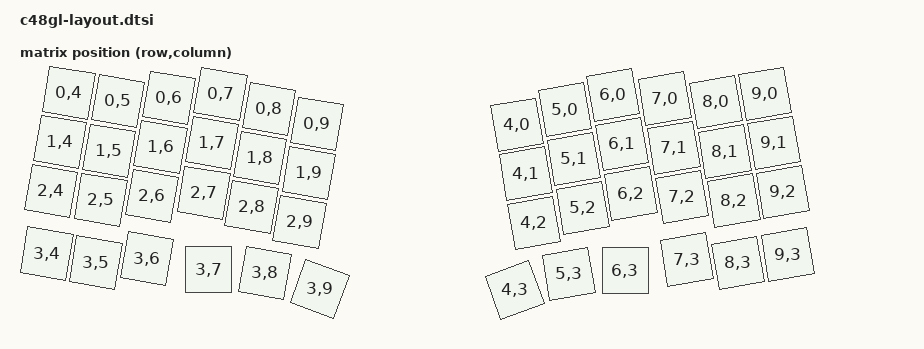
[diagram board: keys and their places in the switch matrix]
// SPDX-License-Identifier: GPL-2.0-or-later
// Generated by scripts/generate_layout.py; do not edit by hand.
// Key order: QMK LAYOUT. Geometry: PCB SW1..SW48, 19.05 mm = 1u.
#include <physical_layouts.dtsi>

/ {
    c48gl_transform: transform {
        compatible = "zmk,matrix-transform";
        rows = <10>;
        columns = <10>;
        map = <
            RC(0,4) RC(0,5) RC(0,6) RC(0,7) RC(0,8) RC(0,9) RC(4,0) RC(5,0) RC(6,0) RC(7,0) RC(8,0) RC(9,0)
            RC(1,4) RC(1,5) RC(1,6) RC(1,7) RC(1,8) RC(1,9) RC(4,1) RC(5,1) RC(6,1) RC(7,1) RC(8,1) RC(9,1)
            RC(2,4) RC(2,5) RC(2,6) RC(2,7) RC(2,8) RC(2,9) RC(4,2) RC(5,2) RC(6,2) RC(7,2) RC(8,2) RC(9,2)
            RC(3,4) RC(3,5) RC(3,6) RC(3,7) RC(3,8) RC(3,9) RC(4,3) RC(5,3) RC(6,3) RC(7,3) RC(8,3) RC(9,3)
        >;
    };

    c48gl_layout: physical_layout {
        compatible = "zmk,physical-layout";
        display-name = "C48GL 48 keys";
        transform = <&c48gl_transform>;
        kscan = <&kscan0>;
        keys =
            <&key_physical_attrs 100 100 94 50 1000 144 100>,
            <&key_physical_attrs 100 100 193 67 1000 243 117>,
            <&key_physical_attrs 100 100 295 60 1000 345 110>,
            <&key_physical_attrs 100 100 398 53 1000 448 103>,
            <&key_physical_attrs 100 100 495 83 1000 545 133>,
            <&key_physical_attrs 100 100 591 112 1000 641 162>,
            <&key_physical_attrs 100 100 991 114 (-1000) 1041 164>,
            <&key_physical_attrs 100 100 1087 84 (-1000) 1137 134>,
            <&key_physical_attrs 100 100 1183 55 (-1000) 1233 105>,
            <&key_physical_attrs 100 100 1286 62 (-1000) 1336 112>,
            <&key_physical_attrs 100 100 1389 69 (-1000) 1439 119>,
            <&key_physical_attrs 100 100 1487 52 (-1000) 1537 102>,
            <&key_physical_attrs 100 100 77 148 1000 127 198>,
            <&key_physical_attrs 100 100 175 166 1000 225 216>,
            <&key_physical_attrs 100 100 278 159 1000 328 209>,
            <&key_physical_attrs 100 100 381 151 1000 431 201>,
            <&key_physical_attrs 100 100 477 181 1000 527 231>,
            <&key_physical_attrs 100 100 574 211 1000 624 261>,
            <&key_physical_attrs 100 100 1008 212 (-1000) 1058 262>,
            <&key_physical_attrs 100 100 1104 183 (-1000) 1154 233>,
            <&key_physical_attrs 100 100 1201 153 (-1000) 1251 203>,
            <&key_physical_attrs 100 100 1304 160 (-1000) 1354 210>,
            <&key_physical_attrs 100 100 1406 168 (-1000) 1456 218>,
            <&key_physical_attrs 100 100 1505 150 (-1000) 1555 200>,
            <&key_physical_attrs 100 100 59 247 1000 109 297>,
            <&key_physical_attrs 100 100 158 264 1000 208 314>,
            <&key_physical_attrs 100 100 261 257 1000 311 307>,
            <&key_physical_attrs 100 100 364 250 1000 414 300>,
            <&key_physical_attrs 100 100 460 279 1000 510 329>,
            <&key_physical_attrs 100 100 556 309 1000 606 359>,
            <&key_physical_attrs 100 100 1025 311 (-1000) 1075 361>,
            <&key_physical_attrs 100 100 1122 281 (-1000) 1172 331>,
            <&key_physical_attrs 100 100 1218 252 (-1000) 1268 302>,
            <&key_physical_attrs 100 100 1321 259 (-1000) 1371 309>,
            <&key_physical_attrs 100 100 1424 266 (-1000) 1474 316>,
            <&key_physical_attrs 100 100 1522 249 (-1000) 1572 299>,
            <&key_physical_attrs 100 100 50 372 1000 100 422>,
            <&key_physical_attrs 100 100 148 390 1000 198 440>,
            <&key_physical_attrs 100 100 251 382 1000 301 432>,
            <&key_physical_attrs 100 100 374 404 0 424 454>,
            <&key_physical_attrs 100 100 487 411 1000 537 461>,
            <&key_physical_attrs 100 100 596 443 2000 646 493>,
            <&key_physical_attrs 100 100 986 445 (-2000) 1036 495>,
            <&key_physical_attrs 100 100 1094 413 (-1000) 1144 463>,
            <&key_physical_attrs 100 100 1207 406 0 1257 456>,
            <&key_physical_attrs 100 100 1330 384 (-1000) 1380 434>,
            <&key_physical_attrs 100 100 1433 391 (-1000) 1483 441>,
            <&key_physical_attrs 100 100 1532 374 (-1000) 1582 424>;
    };
};
